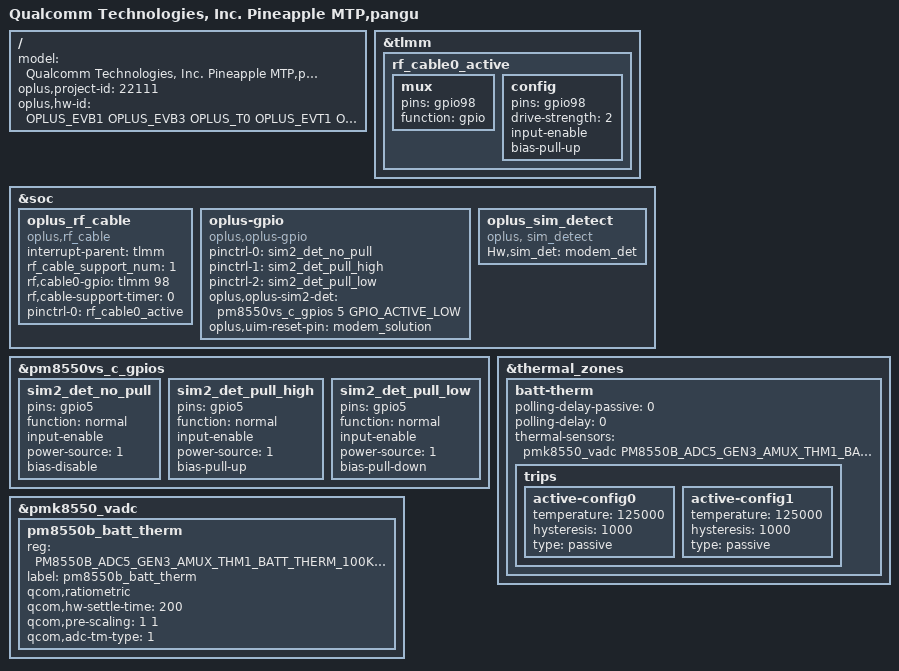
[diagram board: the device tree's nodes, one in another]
/dts-v1/;
/plugin/;
#include <dt-bindings/oplus/hw-id.h>
#include "../qcom/pineapple-mtp-overlay.dts"
#include "pineapple_overlay_common.dtsi"
#include "pangu_overlay_common.dtsi"
#include "oplus_chg/oplus-chg-22111.dtsi"
#include "oplus_misc/oplus-misc-22111.dtsi"
#include "tp/pangu-oplus-tp-22111.dtsi"
#include "oplus_fp/oplus_fp_22111.dtsi"
#include "sensor/pangu-sensor-22111.dtsi"

/ {
    model = "Qualcomm Technologies, Inc. Pineapple MTP,pangu";

    oplus,project-id = <22111>;
    oplus,hw-id = <OPLUS_EVB1 OPLUS_EVB3 OPLUS_T0 OPLUS_EVT1 OPLUS_EVT2 OPLUS_DVT1 OPLUS_DVT2 OPLUS_PVT1>;
};

&tlmm {
  //#ifdef OPLUS_FEATURE_RF_CABLE_DETECT
  rf_cable0_active: rf_cable0_active {
    mux {
      pins = "gpio98";
      function = "gpio";
    };
    config {
      pins = "gpio98";
      drive-strength = <2>;
      input-enable;
      bias-pull-up;
    };
  };
  //#endif /* OPLUS_FEATURE_RF_CABLE_DETECT */
};

&soc {
  //#ifdef OPLUS_FEATURE_RF_CABLE_DETECT
  oplus_rf_cable {
    compatible = "oplus,rf_cable";
    interrupt-parent = <&tlmm>;
    rf_cable_support_num = <1>;
    rf,cable0-gpio = <&tlmm 98 0>;
    rf,cable-support-timer = <0>;
    pinctrl-names = "rf_cable_active";
    pinctrl-0 = <&rf_cable0_active>;
  };
  //#endif /* OPLUS_FEATURE_RF_CABLE_DETECT */

  //#ifdef OPLUS_FEATRUE_DUAL_SIM_DETECT
  oplus-gpio {
    compatible = "oplus,oplus-gpio";
    pinctrl-names = "sim2_det_no_pull", "sim2_det_pull_high", "sim2_det_pull_low";
    pinctrl-0 = <&sim2_det_no_pull>;
    pinctrl-1 = <&sim2_det_pull_high>;
    pinctrl-2 = <&sim2_det_pull_low>;
    oplus,oplus-sim2-det = <&pm8550vs_c_gpios 5 GPIO_ACTIVE_LOW>;
    oplus,uim-reset-pin = "modem_solution";
  };
  oplus_sim_detect {
    compatible = "oplus, sim_detect";
    Hw,sim_det = "modem_det";
  };
    //#endif /* OPLUS_FEATRUE_DUAL_SIM_DETECT */
};


&pm8550vs_c_gpios {
  //#ifdef OPLUS_FEATRUE_DUAL_SIM_DETECT
  sim2_det_no_pull: sim2_det_no_pull {
    pins = "gpio5";
    function = "normal";
    input-enable;
    power-source = <1>;
    bias-disable;
  };

  sim2_det_pull_high: sim2_det_pull_high {
    pins = "gpio5";
    function = "normal";
    input-enable;
    power-source = <1>;
    bias-pull-up;
  };

  sim2_det_pull_low: sim2_det_pull_low {
    pins = "gpio5";
    function = "normal";
    input-enable;
    power-source = <1>;
    bias-pull-down;
  };
  //#endif OPLUS_FEATRUE_DUAL_SIM_DETECT
};

&pmk8550_vadc {
	pm8550b_batt_therm {
		reg = <PM8550B_ADC5_GEN3_AMUX_THM1_BATT_THERM_100K_PU>;
		label = "pm8550b_batt_therm";
		qcom,ratiometric;
		qcom,hw-settle-time = <200>;
		qcom,pre-scaling = <1 1>;
		qcom,adc-tm-type = <1>;
	};
};

&thermal_zones {
	batt-therm {
		polling-delay-passive = <0>;
		polling-delay = <0>;
		thermal-sensors = <&pmk8550_vadc PM8550B_ADC5_GEN3_AMUX_THM1_BATT_THERM_100K_PU>;
		trips {
			active-config0 {
				temperature = <125000>;
				hysteresis = <1000>;
				type = "passive";
			};

			active-config1 {
				temperature = <125000>;
				hysteresis = <1000>;
				type = "passive";
			};
		};
	};
};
